# Montana register map
Vendor: ONSemiconductor; Series: Montana Series; File version: 1.0
CPU: CM33 r0p4, little endian, MPU, FPU, 3 interrupt priority bits
Registers are 32-bit, read-write, reset 0x0 unless marked. A register's access mark holds for its fields unless they carry their own. Offsets are from the block's base; [hi:lo] are bit positions; {n}, {i} and the like mark numbered series; 'fields as' and 'values as' point back to an identical list.

## RF0 (part 1 of 3) — RF Front-End 2.4 GHz
Base 0x40040800
Same registers: RF1 0x40040A00, RF2 0x40040C00, RF3 0x40040E00
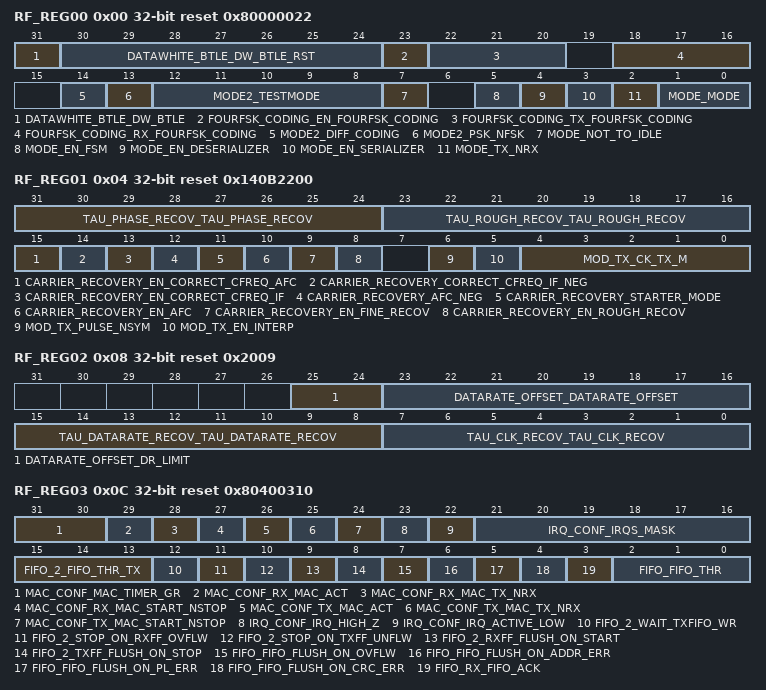
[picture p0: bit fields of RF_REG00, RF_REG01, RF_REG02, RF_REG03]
0x00 RF_REG00 reset 0x80000022 — REG00
  [31] DATAWHITE_BTLE_DW_BTLE — Data whitening control
    0=DATAWHITE_BTLE_DW_BTLE_DISABLE (Disable data whitening); 1=DATAWHITE_BTLE_DW_BTLE_ENABLE (Enable data whitening)
  [30:24] DATAWHITE_BTLE_DW_BTLE_RST — Reset value to put on the Bluetooth LE data whitening shift register
    0=DATAWHITE_BTLE_DW_BTLE_RST_DEFAULT
  [23] FOURFSK_CODING_EN_FOURFSK_CODING — 4FSK coding
    0=FOURFSK_CODING_EN_FOURFSK_CODING_DISABLE (Disable 4FSK coding); 1=FOURFSK_CODING_EN_FOURFSK_CODING_ENABLE (Enable 4FSK coding)
  [22:20] FOURFSK_CODING_TX_FOURFSK_CODING — Set the 4FSK coding (Tx): bit 0 determines if the sign is given by the Q signal (0) or I signal (1), bit 1 select if the signal is inverted for the sign, bit 2 selects if the signal is inverted for the abs amplitude
    0=FOURFSK_CODING_TX_FOURFSK_CODING_DEFAULT
  [18:16] FOURFSK_CODING_RX_FOURFSK_CODING — Set the 4FSK decoding (Rx): bit 0 determines if the sign is given by the Q signal (0) or I signal (1), bit 1 selects if the signal is inverted for the sign, bit 2 selects if the signal is inverted for the abs amplitude
    0=FOURFSK_CODING_RX_FOURFSK_CODING_DEFAULT
  [14] MODE2_DIFF_CODING — Differential coding/decoding
    0=MODE2_DIFF_CODING_DISABLE (Disable the differential coding/decoding); 1=MODE2_DIFF_CODING_ENABLE (Enable the differential coding/decoding)
  [13] MODE2_PSK_NFSK — FSK/PSK mode selection
    0=MODE2_PSK_NFSK_FSK (FSK mode is selected); 1=MODE2_PSK_NFSK_PSK (PSK mode is selected)
  [12:8] MODE2_TESTMODE — Output test mode
    0=MODE2_TESTMODE_OFF; 8=MODE2_TESTMODE_CEVA
  [7] MODE_NOT_TO_IDLE — FSM to go in suspend mode after a Tx or Rx packet
    0=MODE_NOT_TO_IDLE_DISABLE (FSM not to go in suspend mode after a Tx or Rx packet); 1=MODE_NOT_TO_IDLE_ENABLE (FSM to go in suspend mode after a Tx or Rx packet)
  [5] MODE_EN_FSM — Radio FSM control
    0=MODE_EN_FSM_DISABLE (Disable the radio FSM); 1=MODE_EN_FSM_ENABLE (Enable the radio FSM)
  [4] MODE_EN_DESERIALIZER — Deserializer control
    0=MODE_EN_DESERIALIZER_DISABLE (Disable the deserializer); 1=MODE_EN_DESERIALIZER_ENABLE (Enable the deserializer)
  [3] MODE_EN_SERIALIZER — Serializer control
    0=MODE_EN_SERIALIZER_DISABLE (Disable the serializer); 1=MODE_EN_SERIALIZER_ENABLE (Enable the serializer)
  [2] MODE_TX_NRX — Select Tx or Rx mode
    0=MODE_TX_NRX_RX (Select Rx mode); 1=MODE_TX_NRX_TX (Select Tx mode)
  [1:0] MODE_MODE — Select the working mode of the digital baseband
    0=The digital baseband is off; 1=The clock is generated but the blocks are reset (Tx, Rx, FIFOs and FSM); 2=The digital baseband is frozen; 3=Working
0x04 RF_REG01 reset 0x140B2200 — REG01
  [31:24] TAU_PHASE_RECOV_TAU_PHASE_RECOV — Time constant of the fine carrier recovery block
    20=TAU_PHASE_RECOV_TAU_PHASE_RECOV_DEFAULT
  [23:16] TAU_ROUGH_RECOV_TAU_ROUGH_RECOV — Time constant of the rough carrier recovery block
    11=TAU_ROUGH_RECOV_TAU_ROUGH_RECOV_DEFAULT
  [15] CARRIER_RECOVERY_EN_CORRECT_CFREQ_AFC — Automatic AFC correction
    0=CARRIER_RECOVERY_EN_CORRECT_CFREQ_AFC_DISABLE (Disable the automatic AFC correction); 1=CARRIER_RECOVERY_EN_CORRECT_CFREQ_AFC_ENABLE (Enable the automatic AFC correction)
  [14] CARRIER_RECOVERY_CORRECT_CFREQ_IF_NEG — IF correction
    0=CARRIER_RECOVERY_CORRECT_CFREQ_IF_NEG_POS (Positive IF correction); 1=CARRIER_RECOVERY_CORRECT_CFREQ_IF_NEG_NEG (Negative IF correction)
  [13] CARRIER_RECOVERY_EN_CORRECT_CFREQ_IF — Automatic IF correction
    0=CARRIER_RECOVERY_EN_CORRECT_CFREQ_IF_DISABLE (Disable the automatic IF correction); 1=CARRIER_RECOVERY_EN_CORRECT_CFREQ_IF_ENABLE (Enable the automatic IF correction)
  [12] CARRIER_RECOVERY_AFC_NEG — AFC correction
    0=CARRIER_RECOVERY_AFC_NEG_POS (Positive AFC correction); 1=CARRIER_RECOVERY_AFC_NEG_NEG (Negative AFC correction)
  [11] CARRIER_RECOVERY_STARTER_MODE — Starter mode
    0=CARRIER_RECOVERY_STARTER_MODE_DISABLE (Disable the starter mode); 1=CARRIER_RECOVERY_STARTER_MODE_ENABLE (Enable the starter mode (32x faster carrier recovery))
  [10] CARRIER_RECOVERY_EN_AFC — Automatic Frequency Control
    0=CARRIER_RECOVERY_EN_AFC_DISABLE (Disable the Automatic Frequency Control); 1=CARRIER_RECOVERY_EN_AFC_ENABLE (Enable the Automatic Frequency Control)
  [9] CARRIER_RECOVERY_EN_FINE_RECOV — Fine carrier recovery
    0=CARRIER_RECOVERY_EN_FINE_RECOV_DISABLE (Disable the fine carrier recovery); 1=CARRIER_RECOVERY_EN_FINE_RECOV_ENABLE (Enable the fine carrier recovery)
  [8] CARRIER_RECOVERY_EN_ROUGH_RECOV — Rough carrier recovery
    0=CARRIER_RECOVERY_EN_ROUGH_RECOV_DISABLE (Disable the rough carrier recovery); 1=CARRIER_RECOVERY_EN_ROUGH_RECOV_ENABLE (Enable the rough carrier recovery)
  [6] MOD_TX_PULSE_NSYM — Tx pulse shape function.
    0=MOD_TX_PULSE_NSYM_EVEN (Tx pulse shape is an even function); 1=MOD_TX_PULSE_NSYM_ODD (Tx pulse shape is an odd function)
  [5] MOD_TX_EN_INTERP — Tx CIC interpolator
    0=MOD_TX_EN_INTERP_DISABLE (Disable the Tx CIC interpolator); 1=MOD_TX_EN_INTERP_ENABLE (Enable the Tx CIC interpolator)
  [4:0] MOD_TX_CK_TX_M — Unsigned value determining the Tx CIC interpolator frequency. The formula is similar to the evaluation of the oversampling frequency.
    0=MOD_TX_CK_TX_M_DEFAULT
0x08 RF_REG02 reset 0x2009 — REG02
  [25:24] DATARATE_OFFSET_DR_LIMIT — Set the data-rate recovery limits
    0=DATARATE_OFFSET_DR_LIMIT_DEFAULT
  [23:16] DATARATE_OFFSET_DATARATE_OFFSET — Data-rate offset. It is a signed value and the full scale (0x7f) corresponds to a data-rate offset of 12.5 percent.
    0=DATARATE_OFFSET_DATARATE_OFFSET_DEFAULT
  [15:8] TAU_DATARATE_RECOV_TAU_DATARATE_RECOV — Time constant of the data-rate recovery
    32=TAU_DATARATE_RECOV_TAU_DATARATE_RECOV_DEFAULT
  [7:0] TAU_CLK_RECOV_TAU_CLK_RECOV — Time constant of the clock recovery
    9=TAU_CLK_RECOV_TAU_CLK_RECOV_DEFAULT
0x0C RF_REG03 reset 0x80400310 — REG03
  [31:30] MAC_CONF_MAC_TIMER_GR — MAC timer granularity. The granularity is given by (2^(2mac_timer_gr)) x 1us.
    2=MAC_CONF_MAC_TIMER_GR_DEFAULT
  [29] MAC_CONF_RX_MAC_ACT — FSM switch to Rx after Rx
    0=MAC_CONF_RX_MAC_ACT_DISABLE (FSM will not switch to Rx or Tx after an Rx mode); 1=MAC_CONF_RX_MAC_ACT_ENABLE (FSM will switch to Rx or Tx after an Rx mode)
  [28] MAC_CONF_RX_MAC_TX_NRX — FSM switch to Tx after Rx
    0=MAC_CONF_RX_MAC_TX_NRX_DISABLE (FSM will not switch to Tx after an Rx mode, Rx otherwise.); 1=MAC_CONF_RX_MAC_TX_NRX_ENABLE (FSM will switch to Tx after an Rx mode, Rx otherwise.)
  [27] MAC_CONF_RX_MAC_START_NSTOP — MAC timer activation after sync word detection
    0=MAC_CONF_RX_MAC_START_NSTOP_DISABLE (MAC timer is not activated at the reception of the sync word, at the end of the packet otherwise); 1=MAC_CONF_RX_MAC_START_NSTOP_ENABLE (MAC timer is activated at the reception of the sync word, at the end of the packet otherwise)
  [26] MAC_CONF_TX_MAC_ACT — FSM switch to Rx after Tx
    0=MAC_CONF_TX_MAC_ACT_DISABLE (FSM will not switch to Rx or Tx after a Tx mode.); 1=MAC_CONF_TX_MAC_ACT_ENABLE (FSM will switch to Rx or Tx after a Tx mode.)
  [25] MAC_CONF_TX_MAC_TX_NRX — FSM switch to Tx after Tx
    0=MAC_CONF_TX_MAC_TX_NRX_DISABLE (FSM will not switch to Tx after an Tx mode, Rx otherwise); 1=MAC_CONF_TX_MAC_TX_NRX_ENABLE (FSM will switch to Tx after an Tx mode, Rx otherwise)
  [24] MAC_CONF_TX_MAC_START_NSTOP — MAC timer activation after packet transmission
    0=MAC_CONF_TX_MAC_START_NSTOP_DISABLE (MAC timer is not activated at beginning of the packet, otherwise at the end of the packet transmission); 1=MAC_CONF_TX_MAC_START_NSTOP_ENABLE (MAC timer is activated at beginning of the packet, otherwise at the end of the packet transmission)
  [23] IRQ_CONF_IRQ_HIGH_Z — Pads are set to High-Z when the IRQ is not active
    0=IRQ_CONF_IRQ_HIGH_Z_DISABLE (The pads are not set to High-Z when the IRQ is not active); 1=IRQ_CONF_IRQ_HIGH_Z_ENABLE (The pads are set to High-Z when the IRQ is not active)
  [22] IRQ_CONF_IRQ_ACTIVE_LOW — IRQ are active low
    0=IRQ_CONF_IRQ_ACTIVE_LOW_DISABLE (IRQ are active high); 1=IRQ_CONF_IRQ_ACTIVE_LOW_ENABLE (IRQ are active low)
  [21:16] IRQ_CONF_IRQS_MASK — Mask to determine which IRQs are enabled (active high)
    0=IRQ_CONF_IRQS_MASK_DEFAULT (No IRQ enable); 1=IRQ_CONF_IRQS_MASK_TX (Tx IRQ enable); 2=IRQ_CONF_IRQS_MASK_RX_STOP (Rx stop IRQ enable); 4=IRQ_CONF_IRQS_MASK_RECEIVED (Rx received IRQ enable); 8=IRQ_CONF_IRQS_MASK_SYNC (Sync IRQ enable); 16=IRQ_CONF_IRQS_MASK_TX_FIFO (Tx FIFO IRQ enable); 32=IRQ_CONF_IRQS_MASK_RX_FIFO (Rx FIFO IRQ enable)
  [15:13] FIFO_2_FIFO_THR_TX — Threshold indicating the 'almost empty' Tx FIFO state
    0=Tx FIFO threshold is 16 samples; 1=Tx FIFO threshold is 48 samples; 2=Tx FIFO threshold is 80 samples; 3=Tx FIFO threshold is 112 samples; 4=Tx FIFO threshold is 144 samples; 5=Tx FIFO threshold is 176 samples; 6=Tx FIFO threshold is 208 samples; 7=Tx FIFO threshold is 240 samples
  [12] FIFO_2_WAIT_TXFIFO_WR — FSM will wait a Tx FIFO write before starting the Tx in case of an empty Tx FIFO
    0=FIFO_2_WAIT_TXFIFO_WR_DISABLE (FSM will not wait a Tx FIFO write before starting the Tx in case of an empty Tx FIFO); 1=FIFO_2_WAIT_TXFIFO_WR_ENABLE (FSM will wait a Tx FIFO write before starting the Tx in case of an empty Tx FIFO)
  [11] FIFO_2_STOP_ON_RXFF_OVFLW — Stop the reception in case of a FIFO overflow
    0=FIFO_2_STOP_ON_RXFF_OVFLW_DISABLE (Keep the reception in case of a FIFO overflow); 1=FIFO_2_STOP_ON_RXFF_OVFLW_ENABLE (Stop the reception in case of a FIFO overflow)
  [10] FIFO_2_STOP_ON_TXFF_UNFLW — Stop the transmission in case of a FIFO underflow
    0=FIFO_2_STOP_ON_TXFF_UNFLW_DISABLE (Keep the transmission in case of a FIFO underflow); 1=FIFO_2_STOP_ON_TXFF_UNFLW_ENABLE (Stop the transmission in case of a FIFO underflow)
  [9] FIFO_2_RXFF_FLUSH_ON_START — Flush the Rx FIFO when the Rx is enabled, in order to receive a packet with an empty FIFO
    0=FIFO_2_RXFF_FLUSH_ON_START_DISABLE (Keep the Rx FIFO when the Rx is enabled); 1=FIFO_2_RXFF_FLUSH_ON_START_ENABLE (Flush the Rx FIFO when the Rx is enabled, in order to receive a packet with an empty FIFO)
  [8] FIFO_2_TXFF_FLUSH_ON_STOP — Flush the Tx FIFO after the end of a packet transmission in order to have an empty FIFO
    0=FIFO_2_TXFF_FLUSH_ON_STOP_DISABLE (Keep the Tx FIFO after the end of a packet transmission in order to have an empty FIFO); 1=FIFO_2_TXFF_FLUSH_ON_STOP_ENABLE (Flush the Tx FIFO after the end of a packet transmission in order to have an empty FIFO)
  [7] FIFO_FIFO_FLUSH_ON_OVFLW — Overflow FIFO flush control
    0=FIFO_FIFO_FLUSH_ON_OVFLW_DISABLE (Keep the Rx and the FIFO in case of overflow); 1=FIFO_FIFO_FLUSH_ON_OVFLW_ENABLE (Stop the Rx and flush the FIFO in case of overflow)
  [6] FIFO_FIFO_FLUSH_ON_ADDR_ERR — Address error FIFO flush control
    0=FIFO_FIFO_FLUSH_ON_ADDR_ERR_DISABLE (Keep the Rx and the FIFO in case of address error); 1=FIFO_FIFO_FLUSH_ON_ADDR_ERR_ENABLE (Stop the Rx and flush the FIFO in case of address error)
  [5] FIFO_FIFO_FLUSH_ON_PL_ERR — Packet length error FIFO flush control
    0=FIFO_FIFO_FLUSH_ON_PL_ERR_DISABLE (Keep the Rx and the FIFO in case of packet length error); 1=FIFO_FIFO_FLUSH_ON_PL_ERR_ENABLE (Stop the Rx and flush the FIFO in case of packet length error)
  [4] FIFO_FIFO_FLUSH_ON_CRC_ERR — CRC error FIFO flush control
    0=FIFO_FIFO_FLUSH_ON_CRC_ERR_DISABLE (Keep the Rx and the FIFO in case of CRC error); 1=FIFO_FIFO_FLUSH_ON_CRC_ERR_ENABLE (Stop the Rx and flush the FIFO in case of CRC error)
  [3] FIFO_RX_FIFO_ACK — Rx FIFO acknowledgement
    0=FIFO_RX_FIFO_ACK_DISABLE (Rx FIFO doesn't need an acknowledgement (packet received correctly) to change its state); 1=FIFO_RX_FIFO_ACK_ENABLE (Rx FIFO needs an acknowledgement (packet received correctly) to change its state)
  [2:0] FIFO_FIFO_THR — Threshold indicating the 'almost full' Rx FIFO state
    0=Rx FIFO threshold is 240 samples; 1=Rx FIFO threshold is 208 samples; 2=Rx FIFO threshold is 176 samples; 3=Rx FIFO threshold is 144 samples; 4=Rx FIFO threshold is 112 samples; 5=Rx FIFO threshold is 80 samples; 6=Rx FIFO threshold is 48 samples; 7=Rx FIFO threshold is 16 samples
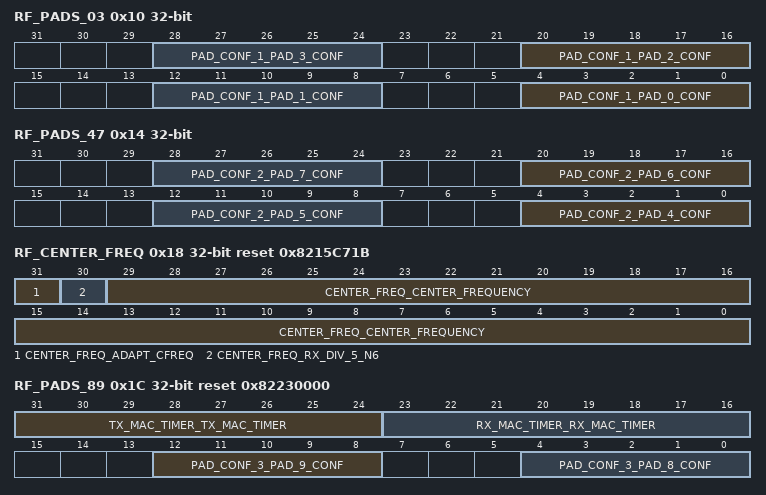
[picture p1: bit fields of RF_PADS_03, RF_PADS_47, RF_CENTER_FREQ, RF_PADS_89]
0x10 RF_PADS_03 — PADS_03
  [8n+4:8n] PAD_CONF_1_PAD_{n}_CONF (n=0..3) — Configuration of GPIO pad {n}
    0=PAD_CONF_1_PAD_{n}_OFF; 15=PAD_CONF_1_PAD_{n}_TEST_MODE
0x14 RF_PADS_47 — PADS_47
  [8n-28:8n-32] PAD_CONF_2_PAD_{n}_CONF (n=4..7) — Configuration of GPIO pad {n}
    0=PAD_CONF_2_PAD_{n}_OFF; 15=PAD_CONF_2_PAD_{n}_TEST_MODE
0x18 RF_CENTER_FREQ reset 0x8215C71B — CENTER_FREQ
  [31] CENTER_FREQ_ADAPT_CFREQ — Frequency adaptation between Tx and Rx.
    0=CENTER_FREQ_ADAPT_CFREQ_DISABLE (Do not adapt frequency between Tx and Rx); 1=CENTER_FREQ_ADAPT_CFREQ_ENABLE (Automatically adapt frequency between Tx and Rx)
  [30] CENTER_FREQ_RX_DIV_5_N6 — Ratio of the PLL reference between Tx and Rx
    0=CENTER_FREQ_RX_DIV_5_N6_DISABLE (The ratio of the PLL reference between Tx and Rx is 6 instead of 5); 1=CENTER_FREQ_RX_DIV_5_N6_ENABLE (The ratio of the PLL reference between Tx and Rx is 5 instead of 6)
  [29:0] CENTER_FREQ_CENTER_FREQUENCY — Set the center frequency
    0x215C71B=CENTER_FREQ_CENTER_FREQUENCY_DEFAULT
0x1C RF_PADS_89 reset 0x82230000 — PADS_89
  [31:24] TX_MAC_TIMER_TX_MAC_TIMER — Time to wait after the Tx mode.
    130=TX_MAC_TIMER_TX_MAC_TIMER_DEFAULT
  [23:16] RX_MAC_TIMER_RX_MAC_TIMER — Time to wait after the Rx mode.
    35=RX_MAC_TIMER_RX_MAC_TIMER_DEFAULT
  [12:8] PAD_CONF_3_PAD_9_CONF — Configuration of GPIO pad 9
    0=PAD_CONF_3_PAD_9_OFF; 15=PAD_CONF_3_PAD_9_TEST_MODE
  [4:0] PAD_CONF_3_PAD_8_CONF — Configuration of GPIO pad 8
    0=PAD_CONF_3_PAD_8_OFF; 15=PAD_CONF_3_PAD_8_TEST_MODE
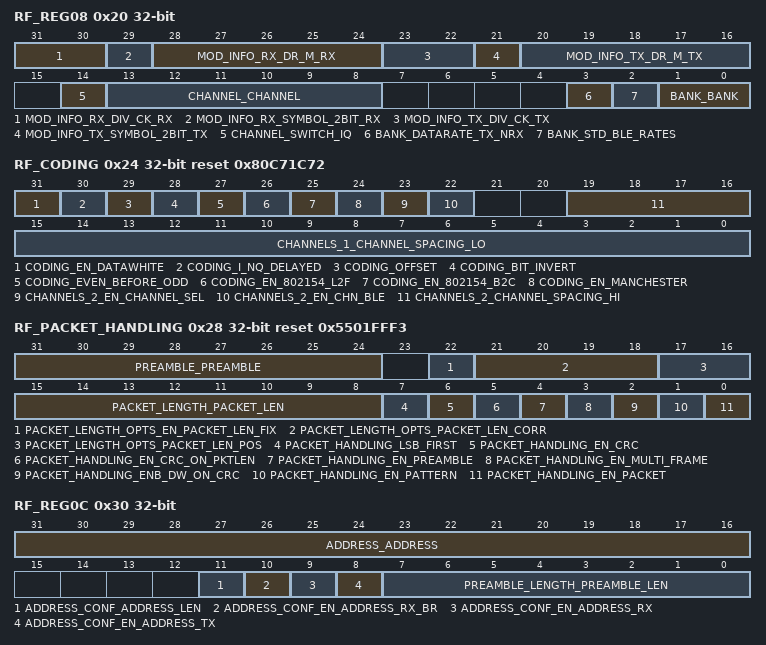
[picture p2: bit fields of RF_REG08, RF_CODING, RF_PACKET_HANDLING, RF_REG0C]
0x20 RF_REG08 — REG08
  [31:30] MOD_INFO_RX_DIV_CK_RX — Set the clock divider for the Rx mode: 00 => /1, 01 => /2, 1x => /3
    0=MOD_INFO_RX_DIV_CK_RX_DEFAULT
  [29] MOD_INFO_RX_SYMBOL_2BIT_RX — Rx symbol bits composition
    0=MOD_INFO_RX_SYMBOL_2BIT_RX_DISABLE (Each symbol is not composed by 2 bits (OQPSK or 4FSK)); 1=MOD_INFO_RX_SYMBOL_2BIT_RX_ENABLE (Each symbol is composed by 2 bits (OQPSK or 4FSK))
  [28:24] MOD_INFO_RX_DR_M_RX — Unsigned value determining the oversampling frequency and consequently the data-rate. This frequency is the system frequency (16 or 24 MHz) divided by this value+1.
    0=MOD_INFO_RX_DR_M_RX_DEFAULT
  [23:22] MOD_INFO_TX_DIV_CK_TX — Set the clock divider for the Tx mode: 00 => /1, 01 => /2, 1x => /3
    0=MOD_INFO_TX_DIV_CK_TX_DEFAULT
  [21] MOD_INFO_TX_SYMBOL_2BIT_TX — Tx symbol bits composition
    0=MOD_INFO_TX_SYMBOL_2BIT_TX_DISABLE (Each symbol is not composed by 2 bits (OQPSK or 4FSK)); 1=MOD_INFO_TX_SYMBOL_2BIT_TX_ENABLE (Each symbol is composed by 2 bits (OQPSK or 4FSK))
  [20:16] MOD_INFO_TX_DR_M_TX — Unsigned value determining the oversampling frequency and consequently the data-rate. This frequency is the system frequency (16 or 24 MHz) divided by this value+1.
    0=MOD_INFO_TX_DR_M_TX_DEFAULT
  [14] CHANNEL_SWITCH_IQ — Switch I and Q channels
    0=CHANNEL_SWITCH_IQ_DISABLE (Don't switch I and Q channels); 1=CHANNEL_SWITCH_IQ_ENABLE (Switch I and Q channels)
  [13:8] CHANNEL_CHANNEL — Channel number
    0=CHANNEL_CHANNEL_DEFAULT
  [3] BANK_DATARATE_TX_NRX — Select the data-rate register
    0=BANK_DATARATE_TX_NRX_RX (Rx data-rate); 1=BANK_DATARATE_TX_NRX_TX (Tx data-rate)
  [2] BANK_STD_BLE_RATES — Select the actual bank behavior
    0=BANK_STD_BLE_RATES_CUSTOM (Custom rates); 1=BANK_STD_BLE_RATES_STANDARD (Standard BLE rates)
  [1:0] BANK_BANK — Select the used bank
    0=BANK_BANK_DEFAULT
0x24 RF_CODING reset 0x80C71C72 — CODING
  [31] CODING_EN_DATAWHITE — Data-whitening enabling
    0=CODING_EN_DATAWHITE_DISABLE (Disable the data-whitening); 1=CODING_EN_DATAWHITE_ENABLE (Enable the data-whitening)
  [30] CODING_I_NQ_DELAYED — Channel I delay
    0=CODING_I_NQ_DELAYED_DISABLE (Channel I is not considered as delayed in case of a 2bit per symbol modulation); 1=CODING_I_NQ_DELAYED_ENABLE (Channel I is considered as delayed in case of a 2bit per symbol modulation)
  [29] CODING_OFFSET — Offset (delay) introduction
    0=CODING_OFFSET_DISABLE (No offset (delay) is introduced in one of the two channels (2 bits per symbol modulation)); 1=CODING_OFFSET_ENABLE (An offset (delay) is introduced in one of the two channels (2 bits per symbol modulation))
  [28] CODING_BIT_INVERT — Bit value inversion (Tx and Rx)
    0=CODING_BIT_INVERT_DISABLE (Original bit value (Tx and Rx)); 1=CODING_BIT_INVERT_ENABLE (Inversed bit value (Tx and Rx))
  [27] CODING_EVEN_BEFORE_ODD — Determine the bit order in case of a 2 bits per symbol modulation: if set to 1 the first bit (bit 0, even) goes to the I path
    0=CODING_EVEN_BEFORE_ODD_DISABLE (Second bit (bit 1, odd) goes to the I path); 1=CODING_EVEN_BEFORE_ODD_ENABLE (First bit (bit 0, even) goes to the I path)
  [26] CODING_EN_802154_L2F — Linear to frequency encoding needed in order to modulate an OQPSK as an MSK
    0=CODING_EN_802154_L2F_DISABLE (Disable the linear to frequency encoding); 1=CODING_EN_802154_L2F_ENABLE (Enable the linear to frequency encoding)
  [25] CODING_EN_802154_B2C — Bit to chips encoding used in the IEEE 802.15.4 standard
    0=CODING_EN_802154_B2C_DISABLE (Disable the bit to chips encoding used in the IEEE 802.15.4 standard); 1=CODING_EN_802154_B2C_ENABLE (Enable the bit to chips encoding used in the IEEE 802.15.4 standard)
  [24] CODING_EN_MANCHESTER — Manchester encoding
    0=CODING_EN_MANCHESTER_DISABLE (Disable the Manchester encoding); 1=CODING_EN_MANCHESTER_ENABLE (Enable the Manchester encoding)
  [23] CHANNELS_2_EN_CHANNEL_SEL — Definition of channels
    0=CHANNELS_2_EN_CHANNEL_SEL_DISABLE (Disable the definition of channels); 1=CHANNELS_2_EN_CHANNEL_SEL_ENABLE (Enable the definition of channels)
  [22] CHANNELS_2_EN_CHN_BLE — BLE channels index LUT (idx 37 => RF channel 0, channel idx 38 => RF channel 12, channel idx 39 => RF channel 39)
    0=CHANNELS_2_EN_CHN_BLE_DISABLE (Disable the BLE channels index LUT); 1=CHANNELS_2_EN_CHN_BLE_ENABLE (Enable the BLE channels index LUT)
  [19:16] CHANNELS_2_CHANNEL_SPACING_HI — Channel spacing: the formula that determines this value is the same as for the central frequency. v=ch_sp/144e6*2^25
    7=CHANNELS_2_CHANNEL_SPACING_HI_DEFAULT
  [15:0] CHANNELS_1_CHANNEL_SPACING_LO — Channel spacing: the formula that determines this value is the same as for the central frequency.
    0x1C72=CHANNELS_1_CHANNEL_SPACING_LO_DEFAULT
0x28 RF_PACKET_HANDLING reset 0x5501FFF3 — PACKET_HANDLING
  [31:24] PREAMBLE_PREAMBLE — Preamble to be inserted
    85=PREAMBLE_PREAMBLE_DEFAULT
  [22] PACKET_LENGTH_OPTS_EN_PACKET_LEN_FIX — Packet length configuration
    0=PACKET_LENGTH_OPTS_EN_PACKET_LEN_FIX_DISABLE (Packet length is not fixed); 1=PACKET_LENGTH_OPTS_EN_PACKET_LEN_FIX_ENABLE (Packet length is fixed and specified in the PACKET_LEN register)
  [21:18] PACKET_LENGTH_OPTS_PACKET_LEN_CORR — Signed value that specifies the correction to apply to the specified packet length (due to differences between standards). The packet length here is specified by the byte number after the packet length byte, with the exclusion of the CRC.
    0=PACKET_LENGTH_OPTS_PACKET_LEN_CORR_DEFAULT
  [17:16] PACKET_LENGTH_OPTS_PACKET_LEN_POS — Unsigned value that specifies the position of the packet length after the pattern
    1=PACKET_LENGTH_OPTS_PACKET_LEN_POS_DEFAULT
  [15:8] PACKET_LENGTH_PACKET_LEN — The packet length in the fixed packet length mode. In the variable packet length mode, it specifies the maximal packet length defined by the standard. In case of error a packet_len_err is raised.
    255=PACKET_LENGTH_PACKET_LEN_DEFAULT
  [7] PACKET_HANDLING_LSB_FIRST — Select LSB or MSB to send first
    0=PACKET_HANDLING_LSB_FIRST_MSB (MSB is the first bit to be sent); 1=PACKET_HANDLING_LSB_FIRST_LSB (LSB is the first bit to be sent)
  [6] PACKET_HANDLING_EN_CRC — Automatic CRC evaluation and insertion
    0=PACKET_HANDLING_EN_CRC_DISABLE (Disable the automatic CRC evaluation and insertion); 1=PACKET_HANDLING_EN_CRC_ENABLE (Enable the automatic CRC evaluation and insertion)
  [5] PACKET_HANDLING_EN_CRC_ON_PKTLEN — CRC calculation on the packet length part of the packet
    0=PACKET_HANDLING_EN_CRC_ON_PKTLEN_DISABLE (Disable the CRC calculation on the packet length part of the packet.); 1=PACKET_HANDLING_EN_CRC_ON_PKTLEN_ENABLE (Enable the CRC calculation on the packet length part of the packet.)
  [4] PACKET_HANDLING_EN_PREAMBLE — Automatic preamble insertion
    0=PACKET_HANDLING_EN_PREAMBLE_DISABLE (Disable the automatic preamble insertion); 1=PACKET_HANDLING_EN_PREAMBLE_ENABLE (Enable the automatic preamble insertion)
  [3] PACKET_HANDLING_EN_MULTI_FRAME — Multi-frame packet
    0=PACKET_HANDLING_EN_MULTI_FRAME_DISABLE (Disable the multi-frame packet (preamble-pattern-data-CRC-data-CRC-...)); 1=PACKET_HANDLING_EN_MULTI_FRAME_ENABLE (Enable the multi-frame packet (preamble-pattern-data-CRC-data-CRC-...))
  [2] PACKET_HANDLING_ENB_DW_ON_CRC — Data-whitening on the CRC (active low)
    0=PACKET_HANDLING_ENB_DW_ON_CRC_DISABLE (Enable the data-whitening on the CRC); 1=PACKET_HANDLING_ENB_DW_ON_CRC_ENABLE (Disable the data-whitening on the CRC)
  [1] PACKET_HANDLING_EN_PATTERN — Automatic pattern insertion and recognition
    0=PACKET_HANDLING_EN_PATTERN_DISABLE (Disable the automatic pattern insertion and recognition); 1=PACKET_HANDLING_EN_PATTERN_ENABLE (Enable the automatic pattern insertion and recognition)
  [0] PACKET_HANDLING_EN_PACKET — Packet handler enabling
    0=PACKET_HANDLING_EN_PACKET_DISABLE (Disable the packet handler); 1=PACKET_HANDLING_EN_PACKET_ENABLE (Enable the packet handler)
0x2C RF_SYNC_PATTERN reset 0x8E89BED6 — SYNC_PATTERN
  [31:0] PATTERN — Pattern (sync word) to be inserted or recognized.
    0x8E89BED6=PATTERN_DEFAULT
0x30 RF_REG0C — REG0C
  [31:16] ADDRESS_ADDRESS — Address of the node
    0=ADDRESS_ADDRESS_DEFAULT
  [11] ADDRESS_CONF_ADDRESS_LEN — Address length selection
    0=Address length is 8 bits; 1=Address length is 16 bits
  [10] ADDRESS_CONF_EN_ADDRESS_RX_BR — Broadcast address detection on Rx
    0=ADDRESS_CONF_EN_ADDRESS_RX_BR_DISABLE (Disable the broadcast address detection on Rx); 1=ADDRESS_CONF_EN_ADDRESS_RX_BR_ENABLE (Enable the broadcast address detection on Rx)
  [9] ADDRESS_CONF_EN_ADDRESS_RX — Address detection on Rx
    0=ADDRESS_CONF_EN_ADDRESS_RX_DISABLE (Disable the address detection on Rx); 1=ADDRESS_CONF_EN_ADDRESS_RX_ENABLE (Enable the address detection on Rx)
  [8] ADDRESS_CONF_EN_ADDRESS_TX — Address insertion on Tx
    0=ADDRESS_CONF_EN_ADDRESS_TX_DISABLE (Disable the address insertion on Tx); 1=ADDRESS_CONF_EN_ADDRESS_TX_ENABLE (Enable the address insertion on Tx)
  [7:0] PREAMBLE_LENGTH_PREAMBLE_LEN — Length of the preamble -1
    0=PREAMBLE_LENGTH_PREAMBLE_LEN_DEFAULT
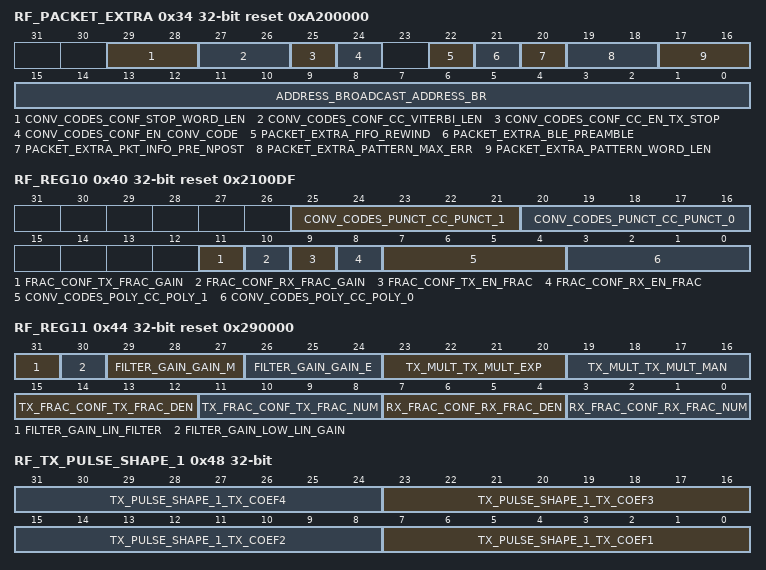
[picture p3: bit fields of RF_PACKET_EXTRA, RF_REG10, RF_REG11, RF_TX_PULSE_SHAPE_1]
0x34 RF_PACKET_EXTRA reset 0xA200000 — PACKET_EXTRA
  [29:28] CONV_CODES_CONF_STOP_WORD_LEN — Length of the stop word, same as the pattern word length
    0=CONV_CODES_CONF_STOP_WORD_LEN_DEFAULT
  [27:26] CONV_CODES_CONF_CC_VITERBI_LEN — Set the memory length of the Viterbi decoder
    0=5; 1=10; 2=20; 3=30
  [25] CONV_CODES_CONF_CC_EN_TX_STOP — Stop word at the end of the transmission
    0=CONV_CODES_CONF_CC_EN_TX_STOP_DISABLE (Disable the stop word at the end of the transmission); 1=CONV_CODES_CONF_CC_EN_TX_STOP_ENABLE (Enable the stop word at the end of the transmission)
  [24] CONV_CODES_CONF_EN_CONV_CODE — Convolutional codes
    0=CONV_CODES_CONF_EN_CONV_CODE_DISABLE (Disable the convolutional codes); 1=CONV_CODES_CONF_EN_CONV_CODE_ENABLE (Enable the convolutional codes)
  [22] PACKET_EXTRA_FIFO_REWIND — At the end of a Tx transmission, the FIFO is rewind to the initial stage
    0=PACKET_EXTRA_FIFO_REWIND_DISABLE (FIFO is not rewind at the end of Tx); 1=PACKET_EXTRA_FIFO_REWIND_ENABLE (FIFO is rewind at the end of Tx)
  [21] PACKET_EXTRA_BLE_PREAMBLE — In Tx the preamble is handled directly (PREAMBLE register is not used) following the BLE standard
    0=PACKET_EXTRA_BLE_PREAMBLE_DISABLE (Preamble register is used); 1=PACKET_EXTRA_BLE_PREAMBLE_ENABLE (Preamble register is not used)
  [20] PACKET_EXTRA_PKT_INFO_PRE_NPOST — Packet information sampling
    0=PACKET_EXTRA_PKT_INFO_PRE_NPOST_SYNC (Sample packet information at the sync word detection); 1=PACKET_EXTRA_PKT_INFO_PRE_NPOST_END (Sample packet information at the end of the packet)
  [19:18] PACKET_EXTRA_PATTERN_MAX_ERR — Unsigned value that specifies the maximum number of errors in the pattern recognition
    0=PACKET_EXTRA_PATTERN_MAX_ERR_DEFAULT
  [17:16] PACKET_EXTRA_PATTERN_WORD_LEN — Pattern word length
    0=8 bits; 1=16 bits; 2=24 bits; 3=32 bits
  [15:0] ADDRESS_BROADCAST_ADDRESS_BR — Broadcast address
    0=ADDRESS_BROADCAST_ADDRESS_BR_DEFAULT
0x38 RF_CRC_POLYNOMIAL reset 0x80032D — CRC_POLYNOMIAL
  [31:0] CRC_POLYNOMIAL_CRC_POLY — CRC polynomial
    0x80032D=CRC_POLYNOMIAL_CRC_POLY_DEFAULT (It is coded using the Koopman notation, i.e. the nth bit codes the (n+1) coefficient.)
0x3C RF_CRC_RST reset 0x555555 — CRC_RST
  [31:0] CRC_RST_CRC_RST — CRC reset value
    0x555555=CRC_RST_CRC_RST_DEFAULT
0x40 RF_REG10 reset 0x2100DF — REG10
  [25:21] CONV_CODES_PUNCT_CC_PUNCT_1 — Puncture of the second convolutional code
    1=CONV_CODES_PUNCT_CC_PUNCT_1_DEFAULT
  [20:16] CONV_CODES_PUNCT_CC_PUNCT_0 — Puncture of the first convolutional code
    1=CONV_CODES_PUNCT_CC_PUNCT_0_DEFAULT
  [11] FRAC_CONF_TX_FRAC_GAIN — Additional gain for fractional data-rates in Tx mode
    0=FRAC_CONF_TX_FRAC_GAIN_DISABLE (Disable the additional gain for fractional data-rates in Tx mode); 1=FRAC_CONF_TX_FRAC_GAIN_ENABLE (Enable the additional gain for fractional data-rates in Tx mode)
  [10] FRAC_CONF_RX_FRAC_GAIN — Additional gain for fractional data-rates in Rx mode
    0=FRAC_CONF_RX_FRAC_GAIN_DISABLE (Disable the additional gain for fractional data-rates in Rx mode); 1=FRAC_CONF_RX_FRAC_GAIN_ENABLE (Enable the additional gain for fractional data-rates in Rx mode)
  [9] FRAC_CONF_TX_EN_FRAC — Fractional data-rates in Tx mode
    0=FRAC_CONF_TX_EN_FRAC_DISABLE (Disable the fractional data-rates in Tx mode); 1=FRAC_CONF_TX_EN_FRAC_ENABLE (Enable the fractional data-rates in Tx mode)
  [8] FRAC_CONF_RX_EN_FRAC — Fractional data-rates in Rx mode
    0=FRAC_CONF_RX_EN_FRAC_DISABLE (Disable the fractional data-rates in Rx mode); 1=FRAC_CONF_RX_EN_FRAC_ENABLE (Enable the fractional data-rates in Rx mode)
  [7:4] CONV_CODES_POLY_CC_POLY_1 — Second convolutional code
    13=CONV_CODES_POLY_CC_POLY_1_DEFAULT
  [3:0] CONV_CODES_POLY_CC_POLY_0 — First convolutional code
    15=CONV_CODES_POLY_CC_POLY_0_DEFAULT
0x44 RF_REG11 reset 0x290000 — REG11
  [31] FILTER_GAIN_LIN_FILTER — Enable the linear filtering
    0=FILTER_GAIN_LIN_FILTER_DISABLE (Disable the linear filtering); 1=FILTER_GAIN_LIN_FILTER_ENABLE (Enable the linear filtering)
  [30] FILTER_GAIN_LOW_LIN_GAIN — Reduce the total gain by 2 (if the linear gain is set)
    0=FILTER_GAIN_LOW_LIN_GAIN_DISABLE (Disable total gain reduction); 1=FILTER_GAIN_LOW_LIN_GAIN_ENABLE (Enable total gain reduction)
  [29:27] FILTER_GAIN_GAIN_M — Mantissa of the final stage gain of the matched filter
    0=FILTER_GAIN_GAIN_M_DEFAULT
  [26:24] FILTER_GAIN_GAIN_E — Exponent of the final stage gain of the matched filter
    0=FILTER_GAIN_GAIN_E_DEFAULT
  [23:20] TX_MULT_TX_MULT_EXP — Exponent of the Tx multiplier
    2=TX_MULT_TX_MULT_EXP_DEFAULT
  [19:16] TX_MULT_TX_MULT_MAN — Mantissa of the Tx multiplier
    9=TX_MULT_TX_MULT_MAN_DEFAULT
  [15:12] TX_FRAC_CONF_TX_FRAC_DEN — Denominator of the fractional data-rate in Tx mode
    0=TX_FRAC_CONF_TX_FRAC_DEN_DEFAULT
  [11:8] TX_FRAC_CONF_TX_FRAC_NUM — Numerator of the fractional data-rate in Tx mode
    0=TX_FRAC_CONF_TX_FRAC_NUM_DEFAULT
  [7:4] RX_FRAC_CONF_RX_FRAC_DEN — Denominator of the fractional data-rate in Rx mode
    0=RX_FRAC_CONF_RX_FRAC_DEN_DEFAULT
  [3:0] RX_FRAC_CONF_RX_FRAC_NUM — Numerator of the fractional data-rate in Rx mode
    0=RX_FRAC_CONF_RX_FRAC_NUM_DEFAULT
0x48 RF_TX_PULSE_SHAPE_1 — TX_PULSE_SHAPE_1
  [8n-1:8n-8] TX_PULSE_SHAPE_1_TX_COEF{n} (n=1..4) — Tx pulse shape coefficient {n}
    0=TX_PULSE_SHAPE_1_TX_COEF{n}_DEFAULT
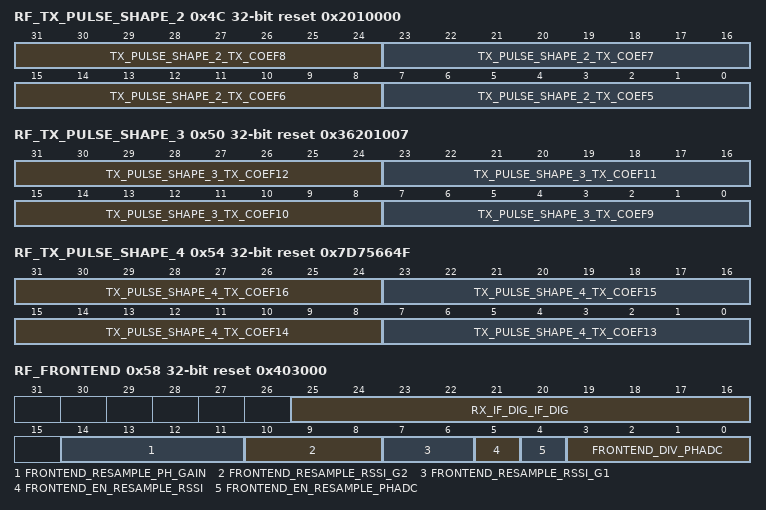
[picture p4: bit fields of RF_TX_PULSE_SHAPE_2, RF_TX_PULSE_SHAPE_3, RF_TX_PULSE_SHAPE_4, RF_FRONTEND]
0x4C RF_TX_PULSE_SHAPE_2 reset 0x2010000 — TX_PULSE_SHAPE_2
  [31:24] TX_PULSE_SHAPE_2_TX_COEF8 — Tx pulse shape coefficient 8
    2=TX_PULSE_SHAPE_2_TX_COEF8_DEFAULT
  [23:16] TX_PULSE_SHAPE_2_TX_COEF7 — Tx pulse shape coefficient 7
    1=TX_PULSE_SHAPE_2_TX_COEF7_DEFAULT
  [15:8] TX_PULSE_SHAPE_2_TX_COEF6 — Tx pulse shape coefficient 6
    0=TX_PULSE_SHAPE_2_TX_COEF6_DEFAULT
  [7:0] TX_PULSE_SHAPE_2_TX_COEF5 — Tx pulse shape coefficient 5
    0=TX_PULSE_SHAPE_2_TX_COEF5_DEFAULT
0x50 RF_TX_PULSE_SHAPE_3 reset 0x36201007 — TX_PULSE_SHAPE_3
  [31:24] TX_PULSE_SHAPE_3_TX_COEF12 — Tx pulse shape coefficient 12
    54=TX_PULSE_SHAPE_3_TX_COEF12_DEFAULT
  [23:16] TX_PULSE_SHAPE_3_TX_COEF11 — Tx pulse shape coefficient 11
    32=TX_PULSE_SHAPE_3_TX_COEF11_DEFAULT
  [15:8] TX_PULSE_SHAPE_3_TX_COEF10 — Tx pulse shape coefficient 10
    16=TX_PULSE_SHAPE_3_TX_COEF10_DEFAULT
  [7:0] TX_PULSE_SHAPE_3_TX_COEF9 — Tx pulse shape coefficient 9
    7=TX_PULSE_SHAPE_3_TX_COEF9_DEFAULT
0x54 RF_TX_PULSE_SHAPE_4 reset 0x7D75664F — TX_PULSE_SHAPE_4
  [31:24] TX_PULSE_SHAPE_4_TX_COEF16 — Tx pulse shape coefficient 16
    125=TX_PULSE_SHAPE_4_TX_COEF16_DEFAULT
  [23:16] TX_PULSE_SHAPE_4_TX_COEF15 — Tx pulse shape coefficient 15
    117=TX_PULSE_SHAPE_4_TX_COEF15_DEFAULT
  [15:8] TX_PULSE_SHAPE_4_TX_COEF14 — Tx pulse shape coefficient 14
    102=TX_PULSE_SHAPE_4_TX_COEF14_DEFAULT
  [7:0] TX_PULSE_SHAPE_4_TX_COEF13 — Tx pulse shape coefficient 13
    79=TX_PULSE_SHAPE_4_TX_COEF13_DEFAULT
0x58 RF_FRONTEND reset 0x403000 — FRONTEND
  [25:16] RX_IF_DIG_IF_DIG — IF frequency (signed)
    64=RX_IF_DIG_IF_DIG_DEFAULT (Should be equal to f_IF/f_phADC*1024)
  [14:11] FRONTEND_RESAMPLE_PH_GAIN — Gain of the phase resampling block
    6=FRONTEND_RESAMPLE_PH_GAIN_DEFAULT
  [10:8] FRONTEND_RESAMPLE_RSSI_G2 — Gain of the decimator in the RSSI resampling block
    0=FRONTEND_RESAMPLE_RSSI_G2_DEFAULT
  [7:6] FRONTEND_RESAMPLE_RSSI_G1 — Gain of the interpolator in the RSSI resampling block
    0=FRONTEND_RESAMPLE_RSSI_G1_DEFAULT
  [5] FRONTEND_EN_RESAMPLE_RSSI — RSSI resampling
    0=FRONTEND_EN_RESAMPLE_RSSI_DISABLE (Disable the RSSI resampling); 1=FRONTEND_EN_RESAMPLE_RSSI_ENABLE (Enable the RSSI resampling)
  [4] FRONTEND_EN_RESAMPLE_PHADC — Phase resampling
    0=FRONTEND_EN_RESAMPLE_PHADC_DISABLE (Disable the phase resampling); 1=FRONTEND_EN_RESAMPLE_PHADC_ENABLE (Enable the phase resampling)
  [3:0] FRONTEND_DIV_PHADC — Unsigned value that specifies the divider to obtain the phADC clock (and RSSI).
    0=FRONTEND_DIV_PHADC_DEFAULT
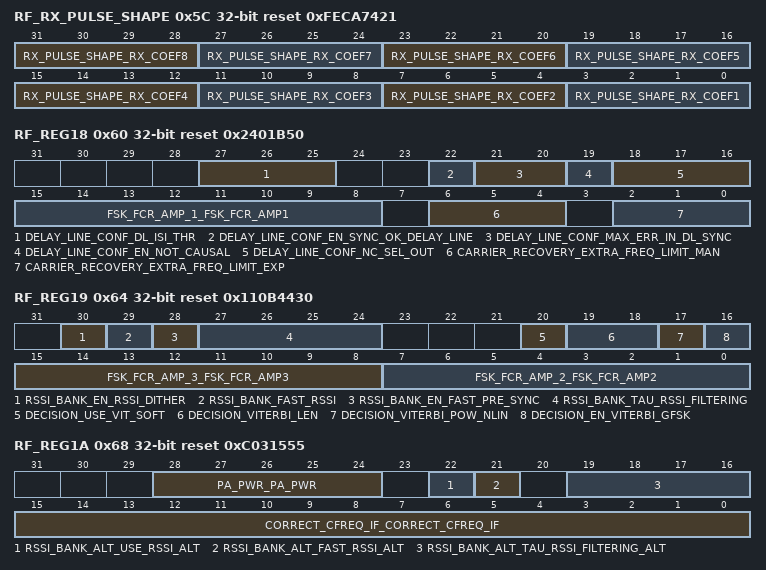
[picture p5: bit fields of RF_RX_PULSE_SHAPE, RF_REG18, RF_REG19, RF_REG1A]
0x5C RF_RX_PULSE_SHAPE reset 0xFECA7421 — RX_PULSE_SHAPE
  [31:28] RX_PULSE_SHAPE_RX_COEF8 — Rx pulse shape coefficient 8
    15=RX_PULSE_SHAPE_RX_COEF8_DEFAULT
  [27:24] RX_PULSE_SHAPE_RX_COEF7 — Rx pulse shape coefficient 7
    14=RX_PULSE_SHAPE_RX_COEF7_DEFAULT
  [23:20] RX_PULSE_SHAPE_RX_COEF6 — Rx pulse shape coefficient 6
    12=RX_PULSE_SHAPE_RX_COEF6_DEFAULT
  [19:16] RX_PULSE_SHAPE_RX_COEF5 — Rx pulse shape coefficient 5
    10=RX_PULSE_SHAPE_RX_COEF5_DEFAULT
  [15:12] RX_PULSE_SHAPE_RX_COEF4 — Rx pulse shape coefficient 4
    7=RX_PULSE_SHAPE_RX_COEF4_DEFAULT
  [11:8] RX_PULSE_SHAPE_RX_COEF3 — Rx pulse shape coefficient 3
    4=RX_PULSE_SHAPE_RX_COEF3_DEFAULT
  [7:4] RX_PULSE_SHAPE_RX_COEF2 — Rx pulse shape coefficient 2
    2=RX_PULSE_SHAPE_RX_COEF2_DEFAULT
  [3:0] RX_PULSE_SHAPE_RX_COEF1 — Rx pulse shape coefficient 1
    1=RX_PULSE_SHAPE_RX_COEF1_DEFAULT
0x60 RF_REG18 reset 0x2401B50 — REG18
  [27:25] DELAY_LINE_CONF_DL_ISI_THR — Threshold bias for ISI compensation in the delay line sync word comparator
    1=DELAY_LINE_CONF_DL_ISI_THR_DEFAULT
  [22] DELAY_LINE_CONF_EN_SYNC_OK_DELAY_LINE — Use pattern_ok signal in delay line to synchronize the deserializer
    0=DELAY_LINE_CONF_EN_SYNC_OK_DELAY_LINE_DISABLE (Don't use the pattern_ok signal in delay line to synchronize the deserializer); 1=DELAY_LINE_CONF_EN_SYNC_OK_DELAY_LINE_ENABLE (Use the pattern_ok signal in delay line to synchronize the deserializer)
  [21:20] DELAY_LINE_CONF_MAX_ERR_IN_DL_SYNC — Set the maximum errors in the delay line sync detection
    0=DELAY_LINE_CONF_MAX_ERR_IN_DL_SYNC_DEFAULT
  [19] DELAY_LINE_CONF_EN_NOT_CAUSAL — Non causal processing
    0=DELAY_LINE_CONF_EN_NOT_CAUSAL_DISABLE (Disable the non causal processing); 1=DELAY_LINE_CONF_EN_NOT_CAUSAL_ENABLE (Enable the non causal processing)
  [18:16] DELAY_LINE_CONF_NC_SEL_OUT — Select the output position for the non causal processing
    0=4 symbols; 1=6 symbols; 2=8 symbols; 3=12 symbols; 4=16 symbols; 5=24 symbols; 6=32 symbols; 7=40 symbols
  [15:8] FSK_FCR_AMP_1_FSK_FCR_AMP1 — FSK amplitude 1 (lowest)
    27=FSK_FCR_AMP_1_FSK_FCR_AMP1_DEFAULT
  [6:4] CARRIER_RECOVERY_EXTRA_FREQ_LIMIT_MAN — Mantissa of the carrier recovery frequency limit (unsigned)
    5=CARRIER_RECOVERY_EXTRA_FREQ_LIMIT_MAN_DEFAULT
  [2:0] CARRIER_RECOVERY_EXTRA_FREQ_LIMIT_EXP — Exponent of the carrier recovery frequency limit (signed)
    0=CARRIER_RECOVERY_EXTRA_FREQ_LIMIT_EXP_DEFAULT
0x64 RF_REG19 reset 0x110B4430 — REG19
  [30] RSSI_BANK_EN_RSSI_DITHER — Speed on the RSSI triangular dithering signal (cf reg RSSI_TUN)
    0=RSSI_BANK_EN_RRSI_DITHER_DISABLE (Disable the RSSI filtering (use minimum value of RSSI even)); 1=RSSI_BANK_EN_RRSI_DITHER_ENABLE (Enable the RSSI filtering)
  [29] RSSI_BANK_FAST_RSSI — RSSI filtering speed
    0=RSSI_BANK_FAST_RSSI_NORMAl (Normal RSSI filtering); 1=RSSI_BANK_FAST_RSSI_FAST (Fast RSSI filtering (8x faster))
  [28] RSSI_BANK_EN_FAST_PRE_SYNC — Fast mode switching during the preamble reception
    0=RSSI_BANK_EN_FAST_PRE_SYNC_DISABLE (Don't switch the fast modes during the preamble reception); 1=RSSI_BANK_EN_FAST_PRE_SYNC_ENABLE (Switch the fast modes during the preamble reception)
  [27:24] RSSI_BANK_TAU_RSSI_FILTERING — Time constant of the RSSI filtering block
    0=4 symbols; 1=8 symbols; 2=16 symbols; 3=32 symbols; 4=64 symbols; 5=128 symbols; 6=256 symbols; 7=512 symbols; 8=1024 symbols
  [20] DECISION_USE_VIT_SOFT — Viterbi soft decoding
    0=DECISION_USE_VIT_SOFT_DISABLE (Don't use the Viterbi soft decoding); 1=DECISION_USE_VIT_SOFT_ENABLE (Use the Viterbi soft decoding)
  [19:18] DECISION_VITERBI_LEN — Set the Viterbi path length
    0=1 bit; 1=2 bits; 2=4 bits; 3=8 bits
  [17] DECISION_VITERBI_POW_NLIN — Viterbi algorithm uses power instead of amplitude to evaluate the error on the path
    0=DECISION_VITERBI_POW_NLIN_DISABLE (Viterbi algorithm uses amplitude to evaluate the error on the path); 1=DECISION_VITERBI_POW_NLIN_ENABLE (Viterbi algorithm uses power to evaluate the error on the path)
  [16] DECISION_EN_VITERBI_GFSK — Viterbi algorithm for the GFSK decoding; this will override the old ISI correction algorithm.
    0=DECISION_EN_VITERBI_GFSK_DISABLE (Disable the Viterbi algorithm for the GFSK decoding); 1=DECISION_EN_VITERBI_GFSK_ENABLE (Enable the Viterbi algorithm for the GFSK decoding)
  [15:8] FSK_FCR_AMP_3_FSK_FCR_AMP3 — FSK amplitude 3 (highest): in 4FSK is the high amplitude (+/-3), in FSK w/ ISI it specifies the highest amplitude (generally it corresponds to a sequence 1-1-1).
    68=FSK_FCR_AMP_3_FSK_FCR_AMP3_DEFAULT
  [7:0] FSK_FCR_AMP_2_FSK_FCR_AMP2 — FSK amplitude 2 (mid): in 4FSK is the threshold, in FSK w/ ISI it specify the mid amplitude (generally it corresponds to a sequence 0-1-1 or 1-1-0).
    48=FSK_FCR_AMP_2_FSK_FCR_AMP2_DEFAULT
0x68 RF_REG1A reset 0xC031555 — REG1A
  [28:24] PA_PWR_PA_PWR — Signed value that sets the PA power
    12=PA_PWR_PA_PWR_DEFAULT
  [22] RSSI_BANK_ALT_USE_RSSI_ALT — Use alternative RRSI configuration
    0=RSSI_BANK_ALT_USE_RSSI_INITIAL (RSSI_AVG, RSSI_MAX and RSSI_MIN will point to initial RSSI configuration); 1=RSSI_BANK_ALT_USE_RSSI_ALTERNATE (RSSI_AVG, RSSI_MAX and RSSI_MIN will point to alternative RSSI configuration)
  [21] RSSI_BANK_ALT_FAST_RSSI_ALT — RSSI filtering speed
    0=RSSI_BANK_ALT_FAST_RSSI_NORMAL (Normal RSSI filtering); 1=RSSI_BANK_ALT_FAST_RSSI_FAST (Fast RSSI filtering (8x faster))
  [19:16] RSSI_BANK_ALT_TAU_RSSI_FILTERING_ALT — Time constant of the RSSI filtering block
    values as RF_REG19.RSSI_BANK_TAU_RSSI_FILTERING
  [15:0] CORRECT_CFREQ_IF_CORRECT_CFREQ_IF — Unsigned value that specifies the IF for the Rx mode.
    0x1555=CORRECT_CFREQ_IF_CORRECT_CFREQ_IF_DEFAULT
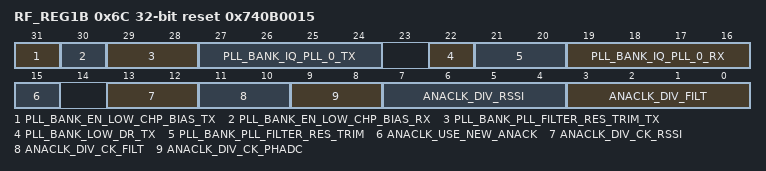
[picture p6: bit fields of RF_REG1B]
0x6C RF_REG1B reset 0x740B0015 — REG1B
  [31] PLL_BANK_EN_LOW_CHP_BIAS_TX — In Rx mode the en_low_chp_bias bit is set to 1
    0=PLL_BANK_EN_LOW_CHP_BIAS_TX_RESET (In Tx mode EN_LOW_CHP_BIAS bit is reset); 1=PLL_BANK_EN_LOW_CHP_BIAS_TX_SET (In Tx mode EN_LOW_CHP_BIAS bit is set)
  [30] PLL_BANK_EN_LOW_CHP_BIAS_RX — In Rx mode the en_low_chp_bias bit is set to 1
    0=PLL_BANK_EN_LOW_CHP_BIAS_RX_RESET (In Rx mode EN_LOW_CHP_BIAS bit is reset); 1=PLL_BANK_EN_LOW_CHP_BIAS_RX_SET (In Rx mode EN_LOW_CHP_BIAS bit is set)
  [29:28] PLL_BANK_PLL_FILTER_RES_TRIM_TX — Same as pll_filter_res_trim but for Tx case. Real value in Tx is pll_filter_res_trim xor pll_filter_res_trim_tx. If set to 0, Tx and Rx have the same value.
    3=PLL_BANK_PLL_FILTER_RES_TRIM_TX_DEFAULT
  [27:24] PLL_BANK_IQ_PLL_0_TX — Charge pump bias for Tx case. Real value in Tx is iq_pll_0 xor iq_pll_0_tx. If set to 0, Tx and Rx have the same value.
    4=PLL_BANK_IQ_PLL_0_TX_DEFAULT
  [22] PLL_BANK_LOW_DR_TX — Low data-rate mode in Tx
    0=PLL_BANK_LOW_DR_TX_DISABLE (Tx works not in low data rate); 1=PLL_BANK_LOW_DR_TX_ENABLE (Tx works in low data rate)
  [21:20] PLL_BANK_PLL_FILTER_RES_TRIM — Allow to modify the value of the loop filter resistor R2 when bit 5 is high (TX mode)
    0=Normal resistor; 1=Normal resistor + 23 percent; 2=Normal resistor + 30 percent; 3=Normal resistor + 70 percent
  [19:16] PLL_BANK_IQ_PLL_0_RX — Charge pump bias for Rx
    11=PLL_BANK_IQ_PLL_0_RX_DEFAULT
  [15] ANACLK_USE_NEW_ANACK — Use the new analog clock generator
    0=ANACLK_USE_NEW_ANACK_DISABLE (Do not use the analog clock generator); 1=ANACLK_USE_NEW_ANACK_ENABLE (Use the analog clock generator)
  [13:12] ANACLK_DIV_CK_RSSI — Set the master clock divider for the RSSI clock (from 48MHz)
    0=Division by 3; 1=Division by 2; 2=Division by 1
  [11:10] ANACLK_DIV_CK_FILT — Set the master clock divider for the channel filter clock (from 48MHz)
    0=Division by 3; 1=Division by 2; 2=Division by 1
  [9:8] ANACLK_DIV_CK_PHADC — Set the master clock divider for the phADC clock (from 48MHz)
    0=Division by 3; 1=Division by 2; 2=Division by 1
  [7:4] ANACLK_DIV_RSSI — Unsigned value that specifies the division factor for the clock controlling the RSSI.
    1=ANACLK_DIV_RSSI_DEFAULT
  [3:0] ANACLK_DIV_FILT — Unsigned value that specifies the division factor for the clock controlling the channel filter.
    5=ANACLK_DIV_FILT_DEFAULT
